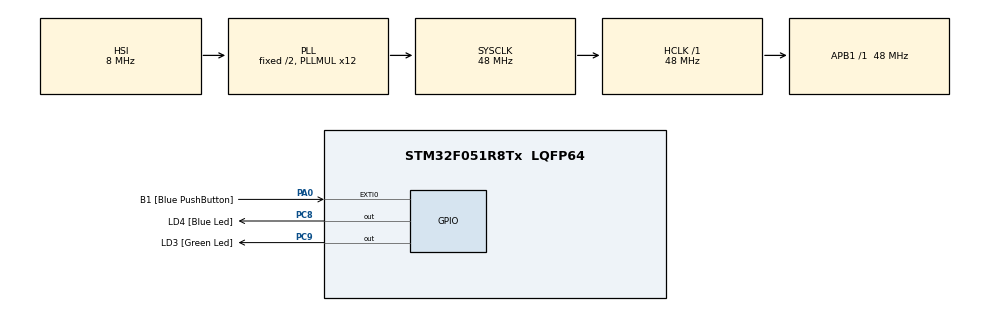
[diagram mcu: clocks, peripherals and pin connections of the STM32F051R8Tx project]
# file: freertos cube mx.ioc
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FREERTOS.Tasks01=defaultTask,0,128,StartDefaultTask,Default
Mcu.Family=STM32F0
Mcu.Name=STM32F051R8Tx
Mcu.Package=LQFP64
NVIC.TIM1_BRK_UP_TRG_COM_IRQn=true\:0\:0\:false\:false\:true\:false
NVIC.TimeBase=TIM1_BRK_UP_TRG_COM_IRQn
NVIC.TimeBaseIP=TIM1
PA0.GPIO_Label=B1 [Blue PushButton]
PA0.GPIO_ModeDefaultEXTI=GPIO_MODE_EVT_RISING
PA0.Signal=GPXTI0
PA13.GPIO_Label=SWDIO
PA13.Signal=SYS_SWDIO
PA14.GPIO_Label=SWCLK
PA14.Signal=SYS_SWCLK
PC8.GPIO_Label=LD4 [Blue Led]
PC8.Signal=GPIO_Output
PC9.GPIO_Label=LD3 [Green Led]
PC9.Signal=GPIO_Output
ProjectManager.HeapSize=0x200
ProjectManager.StackSize=0x400
ProjectManager.TargetToolchain=SW4STM32
RCC.AHBFreq_Value=48000000
RCC.APB1Freq_Value=48000000
RCC.APB1TimFreq_Value=48000000
RCC.HCLKFreq_Value=48000000
RCC.PLLMUL=RCC_PLL_MUL12
RCC.SYSCLKFreq_VALUE=48000000
RCC.SYSCLKSource=RCC_SYSCLKSOURCE_PLLCLK
VP_FREERTOS_VS_ENABLE.Mode=Enabled
VP_SYS_VS_tim1.Mode=TIM1
board=STM32F0DISCOVERY

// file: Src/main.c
/**
  ******************************************************************************
  * File Name          : main.c
  * Description        : Main program body
  ******************************************************************************
  *
  * COPYRIGHT(c) 2016 STMicroelectronics
  *
  * Redistribution and use in source and binary forms, with or without modification,
  * are permitted provided that the following conditions are met:
  *   1. Redistributions of source code must retain the above copyright notice,
  *      this list of conditions and the following disclaimer.
  *   2. Redistributions in binary form must reproduce the above copyright notice,
  *      this list of conditions and the following disclaimer in the documentation
  *      and/or other materials provided with the distribution.
  *   3. Neither the name of STMicroelectronics nor the names of its contributors
  *      may be used to endorse or promote products derived from this software
  *      without specific prior written permission.
  *
  * THIS SOFTWARE IS PROVIDED BY THE COPYRIGHT HOLDERS AND CONTRIBUTORS "AS IS"
  * AND ANY EXPRESS OR IMPLIED WARRANTIES, INCLUDING, BUT NOT LIMITED TO, THE
  * IMPLIED WARRANTIES OF MERCHANTABILITY AND FITNESS FOR A PARTICULAR PURPOSE ARE
  * DISCLAIMED. IN NO EVENT SHALL THE COPYRIGHT HOLDER OR CONTRIBUTORS BE LIABLE
  * FOR ANY DIRECT, INDIRECT, INCIDENTAL, SPECIAL, EXEMPLARY, OR CONSEQUENTIAL
  * DAMAGES (INCLUDING, BUT NOT LIMITED TO, PROCUREMENT OF SUBSTITUTE GOODS OR
  * SERVICES; LOSS OF USE, DATA, OR PROFITS; OR BUSINESS INTERRUPTION) HOWEVER
  * CAUSED AND ON ANY THEORY OF LIABILITY, WHETHER IN CONTRACT, STRICT LIABILITY,
  * OR TORT (INCLUDING NEGLIGENCE OR OTHERWISE) ARISING IN ANY WAY OUT OF THE USE
  * OF THIS SOFTWARE, EVEN IF ADVISED OF THE POSSIBILITY OF SUCH DAMAGE.
  *
  ******************************************************************************
  */
#include "stm32f0xx_hal.h"
#include "cmsis_os.h"
#include "gpio.h"

/* USER CODE BEGIN PV */
/* Private variables ---------------------------------------------------------*/

/* USER CODE END PV */

void SystemClock_Config(void);
void Error_Handler(void);
void MX_FREERTOS_Init(void);

/* USER CODE BEGIN PFP */
/* Private function prototypes -----------------------------------------------*/

/* USER CODE END PFP */

int main(void)
{

  /* MCU Configuration----------------------------------------------------------*/

  /* Reset of all peripherals, Initializes the Flash interface and the Systick. */
  HAL_Init();

  /* Configure the system clock */
  SystemClock_Config();

  /* Initialize all configured peripherals */
  MX_GPIO_Init();

  /* Call init function for freertos objects (in freertos.c) */
  MX_FREERTOS_Init();

  /* Start scheduler */
  osKernelStart();

  /* We should never get here as control is now taken by the scheduler */

  /* Infinite loop */
  while (1)
  {

  }

}

/** System Clock Configuration
*/
void SystemClock_Config(void)
{

  RCC_OscInitTypeDef RCC_OscInitStruct;
  RCC_ClkInitTypeDef RCC_ClkInitStruct;

  RCC_OscInitStruct.OscillatorType = RCC_OSCILLATORTYPE_HSI;
  RCC_OscInitStruct.HSIState = RCC_HSI_ON;
  RCC_OscInitStruct.HSICalibrationValue = 16;
  RCC_OscInitStruct.PLL.PLLState = RCC_PLL_ON;
  RCC_OscInitStruct.PLL.PLLSource = RCC_PLLSOURCE_HSI;
  RCC_OscInitStruct.PLL.PLLMUL = RCC_PLL_MUL12;
  RCC_OscInitStruct.PLL.PREDIV = RCC_PREDIV_DIV1;
  if (HAL_RCC_OscConfig(&RCC_OscInitStruct) != HAL_OK)
  {
    Error_Handler();
  }

  RCC_ClkInitStruct.ClockType = RCC_CLOCKTYPE_HCLK|RCC_CLOCKTYPE_SYSCLK
                              |RCC_CLOCKTYPE_PCLK1;
  RCC_ClkInitStruct.SYSCLKSource = RCC_SYSCLKSOURCE_PLLCLK;
  RCC_ClkInitStruct.AHBCLKDivider = RCC_SYSCLK_DIV1;
  RCC_ClkInitStruct.APB1CLKDivider = RCC_HCLK_DIV1;
  if (HAL_RCC_ClockConfig(&RCC_ClkInitStruct, FLASH_LATENCY_1) != HAL_OK)
  {
    Error_Handler();
  }

  HAL_SYSTICK_Config(HAL_RCC_GetHCLKFreq()/1000);

  HAL_SYSTICK_CLKSourceConfig(SYSTICK_CLKSOURCE_HCLK);

  /* SysTick_IRQn interrupt configuration */
  HAL_NVIC_SetPriority(SysTick_IRQn, 3, 0);
}

void HAL_TIM_PeriodElapsedCallback(TIM_HandleTypeDef *htim)
{
  if (htim->Instance == TIM1) {
    HAL_IncTick();
  }
}

void Error_Handler(void)
{
  while(1)
  {
  }
}

/************************ (C) COPYRIGHT STMicroelectronics *****END OF FILE****/

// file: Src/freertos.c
/**
  ******************************************************************************
  * File Name          : freertos.c
  * Description        : Code for freertos applications
  ******************************************************************************
  *
  * COPYRIGHT(c) 2016 STMicroelectronics
  *
  * Redistribution and use in source and binary forms, with or without modification,
  * are permitted provided that the following conditions are met:
  *   1. Redistributions of source code must retain the above copyright notice,
  *      this list of conditions and the following disclaimer.
  *   2. Redistributions in binary form must reproduce the above copyright notice,
  *      this list of conditions and the following disclaimer in the documentation
  *      and/or other materials provided with the distribution.
  *   3. Neither the name of STMicroelectronics nor the names of its contributors
  *      may be used to endorse or promote products derived from this software
  *      without specific prior written permission.
  *
  * THIS SOFTWARE IS PROVIDED BY THE COPYRIGHT HOLDERS AND CONTRIBUTORS "AS IS"
  * AND ANY EXPRESS OR IMPLIED WARRANTIES, INCLUDING, BUT NOT LIMITED TO, THE
  * IMPLIED WARRANTIES OF MERCHANTABILITY AND FITNESS FOR A PARTICULAR PURPOSE ARE
  * DISCLAIMED. IN NO EVENT SHALL THE COPYRIGHT HOLDER OR CONTRIBUTORS BE LIABLE
  * FOR ANY DIRECT, INDIRECT, INCIDENTAL, SPECIAL, EXEMPLARY, OR CONSEQUENTIAL
  * DAMAGES (INCLUDING, BUT NOT LIMITED TO, PROCUREMENT OF SUBSTITUTE GOODS OR
  * SERVICES; LOSS OF USE, DATA, OR PROFITS; OR BUSINESS INTERRUPTION) HOWEVER
  * CAUSED AND ON ANY THEORY OF LIABILITY, WHETHER IN CONTRACT, STRICT LIABILITY,
  * OR TORT (INCLUDING NEGLIGENCE OR OTHERWISE) ARISING IN ANY WAY OUT OF THE USE
  * OF THIS SOFTWARE, EVEN IF ADVISED OF THE POSSIBILITY OF SUCH DAMAGE.
  *
  ******************************************************************************
  */

#include "FreeRTOS.h"
#include "task.h"
#include "cmsis_os.h"

/* USER CODE BEGIN Includes */
#include "gpio.h"

/* USER CODE END Includes */

osThreadId defaultTaskHandle;

void StartDefaultTask(void const * argument);

void MX_FREERTOS_Init(void); /* (MISRA C 2004 rule 8.1) */

/* Hook prototypes */

/* Init FreeRTOS */

void MX_FREERTOS_Init(void) {

  /* Create the thread(s) */
  /* definition and creation of defaultTask */
  osThreadDef(defaultTask, StartDefaultTask, osPriorityNormal, 0, 128);
  defaultTaskHandle = osThreadCreate(osThread(defaultTask), NULL);

}

/* StartDefaultTask function */
void StartDefaultTask(void const * argument)
{

  /* USER CODE BEGIN StartDefaultTask */
  /* Infinite loop */
  for(;;)
  {
	  HAL_GPIO_TogglePin(GPIOC, GPIO_PIN_8);
	  osDelay(100);
  }
  /* USER CODE END StartDefaultTask */
}

/************************ (C) COPYRIGHT STMicroelectronics *****END OF FILE****/
